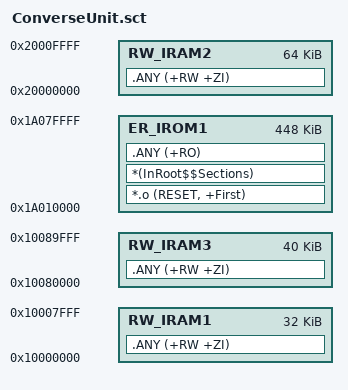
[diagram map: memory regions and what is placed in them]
; *************************************************************
; *** Scatter-Loading Description File generated by uVision ***
; *************************************************************

LR_IROM1 0x1A010000 0x00070000  {    ; load region size_region
  ER_IROM1 0x1A010000 0x00070000  {  ; load address = execution address
   *.o (RESET, +First)
   *(InRoot$$Sections)
   .ANY (+RO)
  }
  RW_IRAM1 0x10000000 0x00008000  {  ; RW data
   .ANY (+RW +ZI)
  }
  RW_IRAM2 0x20000000 0x00010000  {
   .ANY (+RW +ZI)
  }
   RW_IRAM3 0x10080000 0x0000A000  {
   .ANY (+RW +ZI)
  }
}

